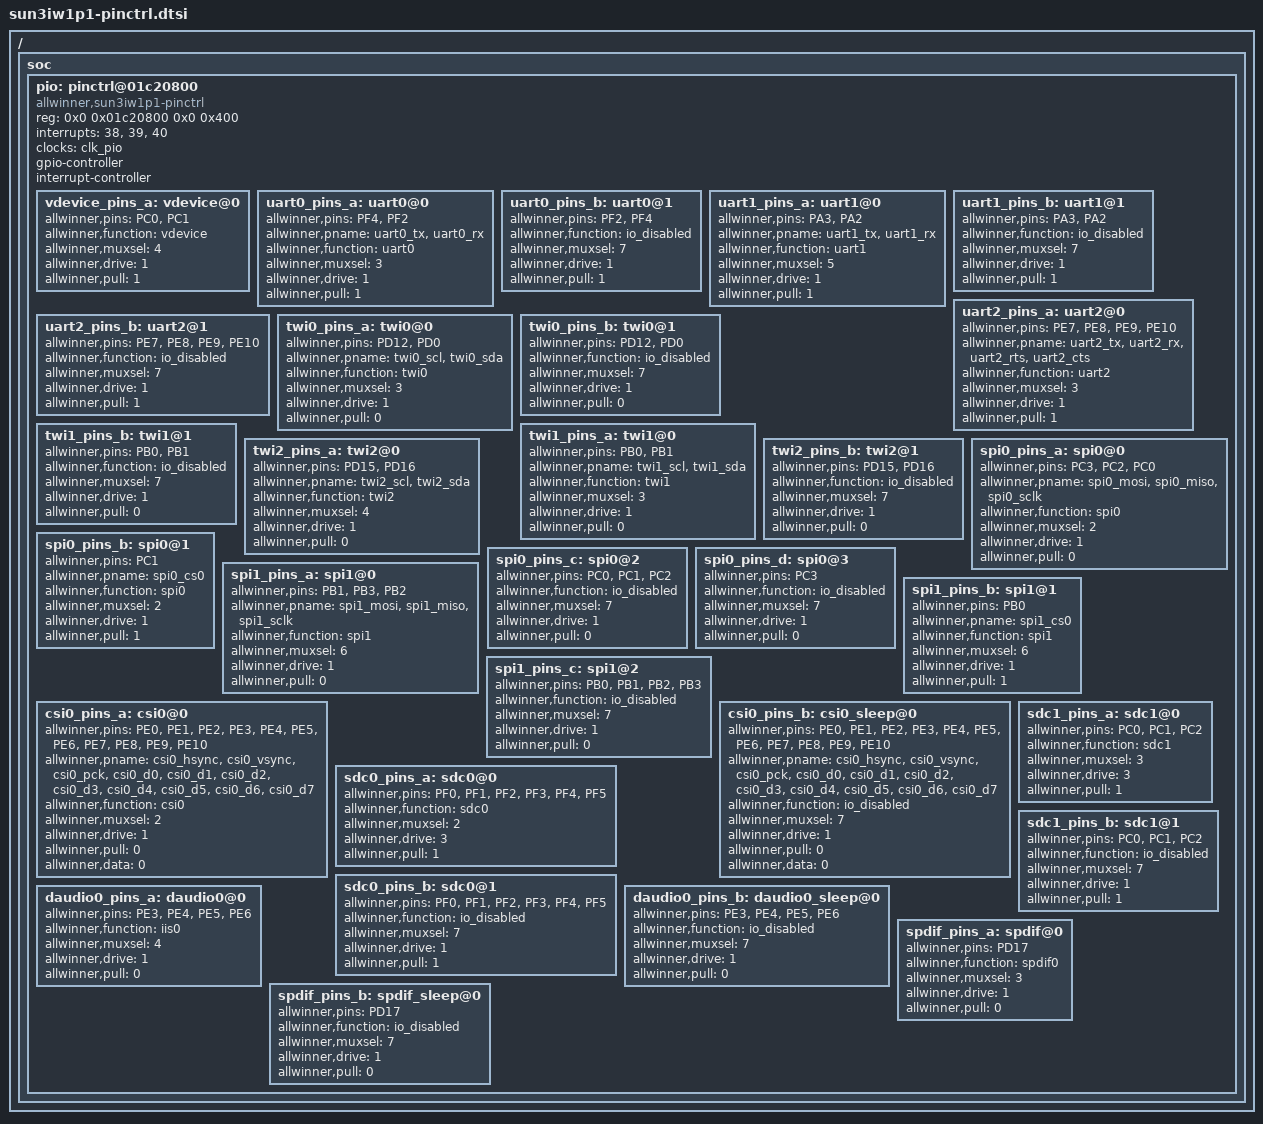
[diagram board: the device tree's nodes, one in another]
/*
 * Allwinner 1663 pin config info.
 */

/ {
    soc: soc {
		pio: pinctrl@01c20800 {
			compatible = "allwinner,sun3iw1p1-pinctrl";
			reg = <0x0 0x01c20800 0x0 0x400>;
			interrupts = <38>,
				     <39>,
				     <40>;
			device_type = "pio";
			clocks = <&clk_pio>;
			gpio-controller;
			interrupt-controller;
			#interrupt-cells = <2>;
			#size-cells = <0>;
			#gpio-cells = <6>;

			vdevice_pins_a: vdevice@0 {
				allwinner,pins = "PC0", "PC1";
				allwinner,function = "vdevice";
				allwinner,muxsel = <4>;
				allwinner,drive = <1>;
				allwinner,pull = <1>;
			};

			uart0_pins_a: uart0@0 {
				allwinner,pins = "PF4", "PF2";
				allwinner,pname = "uart0_tx", "uart0_rx";
				allwinner,function = "uart0";
				allwinner,muxsel = <3>;
				allwinner,drive = <1>;
				allwinner,pull = <1>;
			};

			uart0_pins_b: uart0@1 {
				allwinner,pins = "PF2", "PF4";
				allwinner,function = "io_disabled";
				allwinner,muxsel = <7>;
				allwinner,drive = <1>;
				allwinner,pull = <1>;
			};

			uart1_pins_a: uart1@0 {
				allwinner,pins = "PA3", "PA2";
				allwinner,pname = "uart1_tx", "uart1_rx";
				allwinner,function = "uart1";
				allwinner,muxsel = <5>;
				allwinner,drive = <1>;
				allwinner,pull = <1>;
			};

			uart1_pins_b: uart1@1 {
				allwinner,pins = "PA3", "PA2";
				allwinner,function = "io_disabled";
				allwinner,muxsel = <7>;
				allwinner,drive = <1>;
				allwinner,pull = <1>;
			};

			uart2_pins_a: uart2@0 {
				allwinner,pins = "PE7", "PE8", "PE9", "PE10";
				allwinner,pname = "uart2_tx", "uart2_rx", "uart2_rts", "uart2_cts";
				allwinner,function = "uart2";
				allwinner,muxsel = <3>;
				allwinner,drive = <1>;
				allwinner,pull = <1>;
			};

			uart2_pins_b: uart2@1 {
				allwinner,pins = "PE7", "PE8", "PE9", "PE10";
				allwinner,function = "io_disabled";
				allwinner,muxsel = <7>;
				allwinner,drive = <1>;
				allwinner,pull = <1>;
			};

			twi0_pins_a: twi0@0 {
				allwinner,pins = "PD12", "PD0";
				allwinner,pname = "twi0_scl", "twi0_sda";
				allwinner,function = "twi0";
				allwinner,muxsel = <3>;
				allwinner,drive = <1>;
				allwinner,pull = <0>;
			};

			twi0_pins_b: twi0@1 {
				allwinner,pins = "PD12", "PD0";
				allwinner,function = "io_disabled";
				allwinner,muxsel = <7>;
				allwinner,drive = <1>;
				allwinner,pull = <0>;
			};

			twi1_pins_a: twi1@0 {
				allwinner,pins = "PB0", "PB1";
				allwinner,pname = "twi1_scl", "twi1_sda";
				allwinner,function = "twi1";
				allwinner,muxsel = <3>;
				allwinner,drive = <1>;
				allwinner,pull = <0>;
			};

			twi1_pins_b: twi1@1 {
				allwinner,pins = "PB0", "PB1";
				allwinner,function = "io_disabled";
				allwinner,muxsel = <7>;
				allwinner,drive = <1>;
				allwinner,pull = <0>;
			};

			twi2_pins_a: twi2@0 {
				allwinner,pins = "PD15", "PD16";
				allwinner,pname = "twi2_scl", "twi2_sda";
				allwinner,function = "twi2";
				allwinner,muxsel = <4>;
				allwinner,drive = <1>;
				allwinner,pull = <0>;
			};

			twi2_pins_b: twi2@1 {
				allwinner,pins = "PD15", "PD16";
				allwinner,function = "io_disabled";
				allwinner,muxsel = <7>;
				allwinner,drive = <1>;
				allwinner,pull = <0>;
			};

			spi0_pins_a: spi0@0 {
				allwinner,pins = "PC3", "PC2", "PC0";
				allwinner,pname = "spi0_mosi", "spi0_miso", "spi0_sclk";
				allwinner,function = "spi0";
				allwinner,muxsel = <2>;
				allwinner,drive = <1>;
				allwinner,pull = <0>;
			};

			spi0_pins_b: spi0@1 {
				allwinner,pins = "PC1";
				allwinner,pname = "spi0_cs0";
				allwinner,function = "spi0";
				allwinner,muxsel = <2>;
				allwinner,drive = <1>;
				allwinner,pull = <1>;// only CS should be pulled up
			};

			spi0_pins_c: spi0@2 {
				allwinner,pins = "PC0", "PC1", "PC2";
				allwinner,function = "io_disabled";
				allwinner,muxsel = <7>;
				allwinner,drive = <1>;
				allwinner,pull = <0>;
			};

			spi0_pins_d: spi0@3 {
				allwinner,pins = "PC3";
				allwinner,function = "io_disabled";
				allwinner,muxsel = <7>;
				allwinner,drive = <1>;
				allwinner,pull = <0>;
			};

			spi1_pins_a: spi1@0 {
				allwinner,pins = "PB1", "PB3", "PB2";
				allwinner,pname = "spi1_mosi", "spi1_miso", "spi1_sclk";
				allwinner,function = "spi1";
				allwinner,muxsel = <6>;
				allwinner,drive = <1>;
				allwinner,pull = <0>;
			};

			spi1_pins_b: spi1@1 {
				allwinner,pins = "PB0";
				allwinner,pname = "spi1_cs0";
				allwinner,function = "spi1";
				allwinner,muxsel = <6>;
				allwinner,drive = <1>;
				allwinner,pull = <1>;
			};

			spi1_pins_c: spi1@2 {
				allwinner,pins = "PB0", "PB1", "PB2", "PB3";
				allwinner,function = "io_disabled";
				allwinner,muxsel = <7>;
				allwinner,drive = <1>;
				allwinner,pull = <0>;
			};

			/*zhangchaoxian@hotmail.com*/
			csi0_pins_a: csi0@0 {
				allwinner,pins = "PE0","PE1","PE2","PE3","PE4","PE5","PE6","PE7","PE8","PE9","PE10";
				allwinner,pname = "csi0_hsync","csi0_vsync","csi0_pck","csi0_d0","csi0_d1","csi0_d2",
								"csi0_d3","csi0_d4","csi0_d5","csi0_d6","csi0_d7";
				allwinner,function = "csi0";
				allwinner,muxsel = <2>;
				allwinner,drive = <1>;
				allwinner,pull = <0>;
				allwinner,data = <0>;
			};

			csi0_pins_b: csi0_sleep@0 {
				allwinner,pins = "PE0","PE1","PE2","PE3","PE4","PE5","PE6","PE7","PE8","PE9","PE10";
				allwinner,pname = "csi0_hsync","csi0_vsync","csi0_pck","csi0_d0","csi0_d1","csi0_d2",
								"csi0_d3","csi0_d4","csi0_d5","csi0_d6","csi0_d7";
				allwinner,function = "io_disabled";
				allwinner,muxsel = <7>;
				allwinner,drive = <1>;
				allwinner,pull = <0>;
				allwinner,data = <0>;
			};

			sdc0_pins_a: sdc0@0 {
				allwinner,pins = "PF0", "PF1", "PF2", "PF3","PF4","PF5";
				allwinner,function = "sdc0";
				allwinner,muxsel = <2>;
				allwinner,drive = <3>;
				allwinner,pull = <1>;
			};

			sdc0_pins_b: sdc0@1 {
				allwinner,pins = "PF0", "PF1", "PF2", "PF3","PF4","PF5";
				allwinner,function = "io_disabled";
				allwinner,muxsel = <7>;
				allwinner,drive = <1>;
				allwinner,pull = <1>;
			};

			sdc1_pins_a: sdc1@0 {
				allwinner,pins = "PC0", "PC1", "PC2";
				allwinner,function = "sdc1";
				allwinner,muxsel = <3>;
				allwinner,drive = <3>;
				allwinner,pull = <1>;
			};

			sdc1_pins_b: sdc1@1 {
				allwinner,pins = "PC0", "PC1", "PC2";
				allwinner,function = "io_disabled";
				allwinner,muxsel = <7>;
				allwinner,drive = <1>;
				allwinner,pull = <1>;
			};

			daudio0_pins_a: daudio0@0 {
				allwinner,pins = "PE3", "PE4", "PE5", "PE6";
				allwinner,function = "iis0";
				allwinner,muxsel = <4>;
				allwinner,drive = <1>;
				allwinner,pull = <0>;
			};
			daudio0_pins_b: daudio0_sleep@0 {
				allwinner,pins = "PE3", "PE4", "PE5", "PE6";
				allwinner,function = "io_disabled";
				allwinner,muxsel = <7>;
				allwinner,drive = <1>;
				allwinner,pull = <0>;
			};

			spdif_pins_a: spdif@0 {
				allwinner,pins = "PD17";
				allwinner,function = "spdif0";
				allwinner,muxsel = <3>;
				allwinner,drive = <1>;
				allwinner,pull = <0>;
			};

			spdif_pins_b: spdif_sleep@0 {
				allwinner,pins = "PD17";
				allwinner,function = "io_disabled";
				allwinner,muxsel = <7>;
				allwinner,drive = <1>;
				allwinner,pull = <0>;
			};
		};
	};
};
